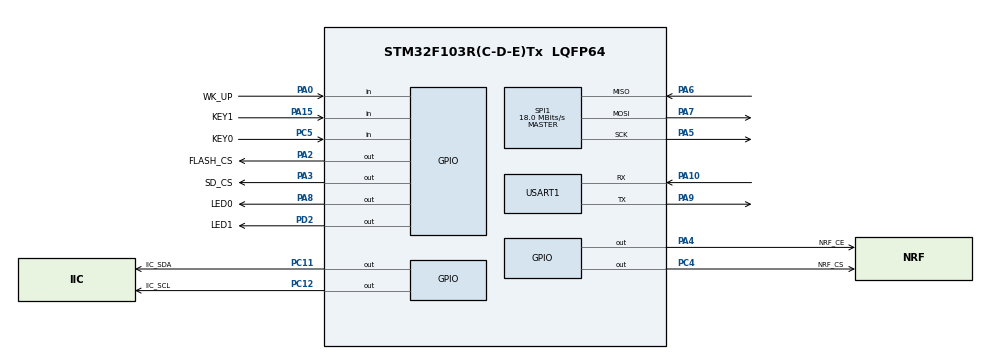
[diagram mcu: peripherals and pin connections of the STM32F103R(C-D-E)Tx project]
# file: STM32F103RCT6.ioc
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Mcu.Family=STM32F1
Mcu.Name=STM32F103R(C-D-E)Tx
Mcu.Package=LQFP64
NVIC.PriorityGroup=NVIC_PRIORITYGROUP_4
NVIC.TIM6_IRQn=true\:4\:0\:true\:false\:true\:true
NVIC.USART1_IRQn=true\:0\:0\:false\:false\:true\:true
PA0-WKUP.GPIO_Label=WK_UP
PA0-WKUP.GPIO_PuPd=GPIO_PULLDOWN
PA0-WKUP.Signal=GPIO_Input
PA10.Mode=Asynchronous
PA10.Signal=USART1_RX
PA13.Mode=Trace_Asynchronous_SW
PA13.Signal=SYS_JTMS-SWDIO
PA14.Mode=Trace_Asynchronous_SW
PA14.Signal=SYS_JTCK-SWCLK
PA15.GPIO_Label=KEY1
PA15.GPIO_PuPd=GPIO_PULLUP
PA15.Signal=GPIO_Input
PA2.GPIO_Label=FLASH_CS
PA2.GPIO_Speed=GPIO_SPEED_FREQ_HIGH
PA2.PinState=GPIO_PIN_SET
PA2.Signal=GPIO_Output
PA3.GPIO_Label=SD_CS
PA3.GPIO_Speed=GPIO_SPEED_FREQ_HIGH
PA3.PinState=GPIO_PIN_SET
PA3.Signal=GPIO_Output
PA4.GPIO_Label=NRF_CE
PA4.GPIO_Speed=GPIO_SPEED_FREQ_HIGH
PA4.PinState=GPIO_PIN_SET
PA4.Signal=GPIO_Output
PA5.Mode=Full_Duplex_Master
PA5.Signal=SPI1_SCK
PA6.Mode=Full_Duplex_Master
PA6.Signal=SPI1_MISO
PA7.Mode=Full_Duplex_Master
PA7.Signal=SPI1_MOSI
PA8.GPIO_Label=LED0
PA8.GPIO_Speed=GPIO_SPEED_FREQ_HIGH
PA8.PinState=GPIO_PIN_SET
PA8.Signal=GPIO_Output
PA9.Mode=Asynchronous
PA9.Signal=USART1_TX
PB3.Mode=Trace_Asynchronous_SW
PB3.Signal=SYS_JTDO-TRACESWO
PC11.GPIO_Label=IIC_SDA
PC11.GPIO_ModeDefaultOutputPP=GPIO_MODE_OUTPUT_OD
PC11.GPIO_Speed=GPIO_SPEED_FREQ_HIGH
PC11.PinState=GPIO_PIN_SET
PC11.Signal=GPIO_Output
PC12.GPIO_Label=IIC_SCL
PC12.GPIO_Speed=GPIO_SPEED_FREQ_HIGH
PC12.PinState=GPIO_PIN_SET
PC12.Signal=GPIO_Output
PC4.GPIO_Label=NRF_CS
PC4.GPIO_Speed=GPIO_SPEED_FREQ_HIGH
PC4.PinState=GPIO_PIN_SET
PC4.Signal=GPIO_Output
PC5.GPIO_Label=KEY0
PC5.GPIO_PuPd=GPIO_PULLUP
PC5.Signal=GPIO_Input
PD0-OSC_IN.Mode=HSE-External-Oscillator
PD0-OSC_IN.Signal=RCC_OSC_IN
PD1-OSC_OUT.Mode=HSE-External-Oscillator
PD1-OSC_OUT.Signal=RCC_OSC_OUT
PD2.GPIO_Label=LED1
PD2.GPIO_Speed=GPIO_SPEED_FREQ_HIGH
PD2.PinState=GPIO_PIN_SET
PD2.Signal=GPIO_Output
ProjectManager.HeapSize=0x200
ProjectManager.StackSize=0x400
ProjectManager.TargetToolchain=MDK-ARM V5
RCC.AHBFreq_Value=72000000
RCC.APB1CLKDivider=RCC_HCLK_DIV2
RCC.APB1Freq_Value=36000000
RCC.APB1TimFreq_Value=72000000
RCC.APB2Freq_Value=72000000
RCC.APB2TimFreq_Value=72000000
RCC.HCLKFreq_Value=72000000
RCC.PLLMUL=RCC_PLL_MUL9
RCC.PLLSourceVirtual=RCC_PLLSOURCE_HSE
RCC.SYSCLKFreq_VALUE=72000000
RCC.SYSCLKSource=RCC_SYSCLKSOURCE_PLLCLK
RCC.USBFreq_Value=72000000
SPI1.BaudRatePrescaler=SPI_BAUDRATEPRESCALER_4
SPI1.CalculateBaudRate=18.0 MBits/s
SPI1.Direction=SPI_DIRECTION_2LINES
SPI1.Mode=SPI_MODE_MASTER
SPI1.VirtualType=VM_MASTER
TIM6.Period=999
TIM6.Prescaler=71
USART1.VirtualMode=VM_ASYNC
VP_TIM6_VS_ClockSourceINT.Mode=Enable_Timer
board=custom

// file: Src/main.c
/* USER CODE BEGIN Header */
/**
  ******************************************************************************
  * @file           : main.c
  * @brief          : Main program body
  ******************************************************************************
  ** This notice applies to any and all portions of this file
  * that are not between comment pairs USER CODE BEGIN and
  * USER CODE END. Other portions of this file, whether
  * inserted by the user or by software development tools
  * are owned by their respective copyright owners.
  *
  * COPYRIGHT(c) 2020 STMicroelectronics
  *
  * Redistribution and use in source and binary forms, with or without modification,
  * are permitted provided that the following conditions are met:
  *   1. Redistributions of source code must retain the above copyright notice,
  *      this list of conditions and the following disclaimer.
  *   2. Redistributions in binary form must reproduce the above copyright notice,
  *      this list of conditions and the following disclaimer in the documentation
  *      and/or other materials provided with the distribution.
  *   3. Neither the name of STMicroelectronics nor the names of its contributors
  *      may be used to endorse or promote products derived from this software
  *      without specific prior written permission.
  *
  * THIS SOFTWARE IS PROVIDED BY THE COPYRIGHT HOLDERS AND CONTRIBUTORS "AS IS"
  * AND ANY EXPRESS OR IMPLIED WARRANTIES, INCLUDING, BUT NOT LIMITED TO, THE
  * IMPLIED WARRANTIES OF MERCHANTABILITY AND FITNESS FOR A PARTICULAR PURPOSE ARE
  * DISCLAIMED. IN NO EVENT SHALL THE COPYRIGHT HOLDER OR CONTRIBUTORS BE LIABLE
  * FOR ANY DIRECT, INDIRECT, INCIDENTAL, SPECIAL, EXEMPLARY, OR CONSEQUENTIAL
  * DAMAGES (INCLUDING, BUT NOT LIMITED TO, PROCUREMENT OF SUBSTITUTE GOODS OR
  * SERVICES; LOSS OF USE, DATA, OR PROFITS; OR BUSINESS INTERRUPTION) HOWEVER
  * CAUSED AND ON ANY THEORY OF LIABILITY, WHETHER IN CONTRACT, STRICT LIABILITY,
  * OR TORT (INCLUDING NEGLIGENCE OR OTHERWISE) ARISING IN ANY WAY OUT OF THE USE
  * OF THIS SOFTWARE, EVEN IF ADVISED OF THE POSSIBILITY OF SUCH DAMAGE.
  *
  ******************************************************************************
  */
/* USER CODE END Header */

#include "main.h"
#include "spi.h"
#include "tim.h"
#include "usart.h"
#include "gpio.h"

void SystemClock_Config(void);

int main(void)
{
    /* MCU Configuration--------------------------------------------------------*/
    /* Reset of all peripherals, Initializes the Flash interface and the Systick. */
    LL_APB2_GRP1_EnableClock(LL_APB2_GRP1_PERIPH_AFIO);
    LL_APB1_GRP1_EnableClock(LL_APB1_GRP1_PERIPH_PWR);
    NVIC_SetPriorityGrouping(NVIC_PRIORITYGROUP_4);
    /* System interrupt init*/
    /**NOJTAG: JTAG-DP Disabled and SW-DP Enabled
    */
    LL_GPIO_AF_Remap_SWJ_NOJTAG();
    /* Configure the system clock */
    SystemClock_Config();
    /* Initialize all configured peripherals */
    MX_GPIO_Init();
    MX_USART1_UART_Init();
    MX_SPI1_Init();
    MX_TIM6_Init();
    /* USER CODE BEGIN 2 */
    LL_TIM_EnableIT_UPDATE(TIM6);
    LL_TIM_EnableCounter(TIM6);

    /* USER CODE END 2 */

    /* Infinite loop */
    /* USER CODE BEGIN WHILE */
    while (1)
    {
        LL_mDelay(500);
        LL_GPIO_TogglePin(LED0_GPIO_Port, LED0_Pin);
        LL_GPIO_TogglePin(LED1_GPIO_Port, LED1_Pin);
        /* USER CODE END WHILE */
    }
}

void SystemClock_Config(void)
{
    LL_FLASH_SetLatency(LL_FLASH_LATENCY_2);

    if (LL_FLASH_GetLatency() != LL_FLASH_LATENCY_2)
    {
        Error_Handler();
    }

    LL_RCC_HSE_Enable();

    /* Wait till HSE is ready */
    while (LL_RCC_HSE_IsReady() != 1)
    {
    }

    LL_RCC_PLL_ConfigDomain_SYS(LL_RCC_PLLSOURCE_HSE_DIV_1, LL_RCC_PLL_MUL_9);
    LL_RCC_PLL_Enable();

    /* Wait till PLL is ready */
    while (LL_RCC_PLL_IsReady() != 1)
    {
    }

    LL_RCC_SetAHBPrescaler(LL_RCC_SYSCLK_DIV_1);
    LL_RCC_SetAPB1Prescaler(LL_RCC_APB1_DIV_2);
    LL_RCC_SetAPB2Prescaler(LL_RCC_APB2_DIV_1);
    LL_RCC_SetSysClkSource(LL_RCC_SYS_CLKSOURCE_PLL);

    /* Wait till System clock is ready */
    while (LL_RCC_GetSysClkSource() != LL_RCC_SYS_CLKSOURCE_STATUS_PLL)
    {
    }

    LL_Init1msTick(72000000);
    LL_SYSTICK_SetClkSource(LL_SYSTICK_CLKSOURCE_HCLK);
    LL_SetSystemCoreClock(72000000);
}

void Error_Handler(void)
{
}

/************************ (C) COPYRIGHT STMicroelectronics *****END OF FILE****/
